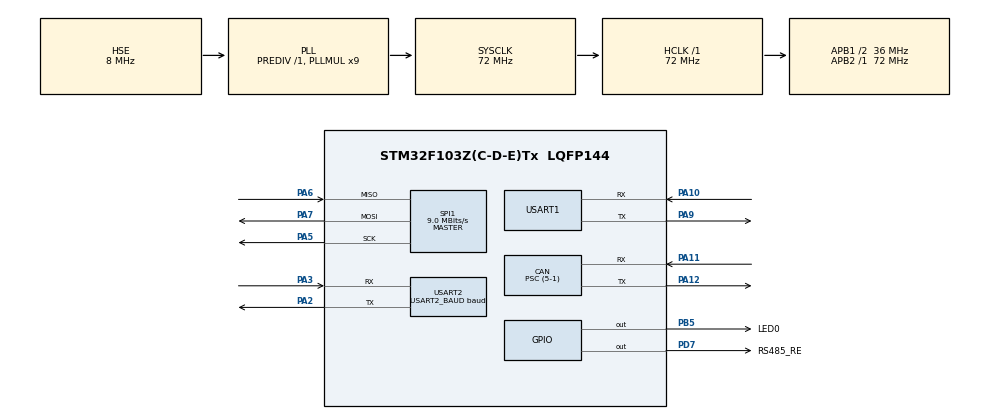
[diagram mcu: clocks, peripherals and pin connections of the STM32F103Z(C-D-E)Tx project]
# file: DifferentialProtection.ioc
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CAN.BS1=CAN_BS1_9TQ
CAN.BS2=CAN_BS2_8TQ
CAN.CalculateBaudRate=500000
CAN.CalculateTimeBit=1999.99
CAN.CalculateTimeQuantum=111.11111111111111
CAN.Mode=CAN_MODE_LOOPBACK
CAN.Prescaler=(5-1)
CAN.SJW=CAN_SJW_4TQ
Mcu.Family=STM32F1
Mcu.Name=STM32F103Z(C-D-E)Tx
Mcu.Package=LQFP144
Mcu.UserConstants=TIMER3_PSC,(72-1);TIMER3_PERIOD,10000;USART2_BAUD,115200
NVIC.CAN1_RX1_IRQn=true\:0\:0\:false\:false\:true\:true\:true
NVIC.PriorityGroup=NVIC_PRIORITYGROUP_2
NVIC.SPI1_IRQn=true\:0\:0\:false\:false\:true\:true\:true
NVIC.TIM3_IRQn=true\:0\:1\:false\:false\:true\:true\:true
NVIC.USART1_IRQn=true\:0\:0\:false\:false\:true\:true\:true
NVIC.USART2_IRQn=true\:0\:0\:false\:false\:true\:true\:true
OSC_IN.Mode=HSE-External-Oscillator
OSC_IN.Signal=RCC_OSC_IN
OSC_OUT.Mode=HSE-External-Oscillator
OSC_OUT.Signal=RCC_OSC_OUT
PA10.Mode=Asynchronous
PA10.Signal=USART1_RX
PA11.Mode=CAN_Activate
PA11.Signal=CAN_RX
PA12.Mode=CAN_Activate
PA12.Signal=CAN_TX
PA13.Mode=JTAG_5_pins
PA13.Signal=SYS_JTMS-SWDIO
PA14.Mode=JTAG_5_pins
PA14.Signal=SYS_JTCK-SWCLK
PA15.Mode=JTAG_5_pins
PA15.Signal=SYS_JTDI
PA2.Mode=Asynchronous
PA2.Signal=USART2_TX
PA3.Mode=Asynchronous
PA3.Signal=USART2_RX
PA5.Mode=Full_Duplex_Master
PA5.Signal=SPI1_SCK
PA6.Mode=Full_Duplex_Master
PA6.Signal=SPI1_MISO
PA7.Mode=Full_Duplex_Master
PA7.Signal=SPI1_MOSI
PA9.Mode=Asynchronous
PA9.Signal=USART1_TX
PB3.Mode=JTAG_5_pins
PB3.Signal=SYS_JTDO-TRACESWO
PB4.Mode=JTAG_5_pins
PB4.Signal=SYS_NJTRST
PB5.GPIO_Label=LED0
PB5.GPIO_PuPd=GPIO_PULLDOWN
PB5.PinState=GPIO_PIN_RESET
PB5.Signal=GPIO_Output
PC14-OSC32_IN.Mode=LSE-External-Oscillator
PC14-OSC32_IN.Signal=RCC_OSC32_IN
PC15-OSC32_OUT.Mode=LSE-External-Oscillator
PC15-OSC32_OUT.Signal=RCC_OSC32_OUT
PD7.GPIO_Label=RS485_RE
PD7.GPIO_Speed=GPIO_SPEED_FREQ_HIGH
PD7.PinState=GPIO_PIN_RESET
PD7.Signal=GPIO_Output
ProjectManager.HeapSize=0x200
ProjectManager.StackSize=0x400
ProjectManager.TargetToolchain=MDK-ARM V5.32
RCC.AHBFreq_Value=72000000
RCC.APB1CLKDivider=RCC_HCLK_DIV2
RCC.APB1Freq_Value=36000000
RCC.APB1TimFreq_Value=72000000
RCC.APB2Freq_Value=72000000
RCC.APB2TimFreq_Value=72000000
RCC.HCLKFreq_Value=72000000
RCC.PLLMUL=RCC_PLL_MUL9
RCC.PLLSourceVirtual=RCC_PLLSOURCE_HSE
RCC.SYSCLKFreq_VALUE=72000000
RCC.SYSCLKSource=RCC_SYSCLKSOURCE_PLLCLK
RCC.USBFreq_Value=72000000
SPI1.BaudRatePrescaler=SPI_BAUDRATEPRESCALER_8
SPI1.CalculateBaudRate=9.0 MBits/s
SPI1.Direction=SPI_DIRECTION_2LINES
SPI1.Mode=SPI_MODE_MASTER
SPI1.VirtualType=VM_MASTER
TIM3.AutoReloadPreload=TIM_AUTORELOAD_PRELOAD_ENABLE
TIM3.Period=TIMER3_PERIOD
TIM3.Prescaler=TIMER3_PSC
USART1.VirtualMode=VM_ASYNC
USART2.BaudRate=USART2_BAUD
USART2.VirtualMode=VM_ASYNC
VP_TIM3_VS_ClockSourceINT.Mode=Internal
board=custom

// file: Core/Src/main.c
/* USER CODE BEGIN Header */
/**
 ******************************************************************************
 * @file           : main.c
 * @brief          : Main program body
 ******************************************************************************
 * @attention
 *
 * <h2><center>&copy; Copyright (c) 2021 STMicroelectronics.
 * All rights reserved.</center></h2>
 *
 * This software component is licensed by ST under BSD 3-Clause license,
 * the "License"; You may not use this file except in compliance with the
 * License. You may obtain a copy of the License at:
 *                        opensource.org/licenses/BSD-3-Clause
 *
 ******************************************************************************
 */
/* USER CODE END Header */
#include "main.h"
#include "can.h"
#include "spi.h"
#include "tim.h"
#include "usart.h"
#include "gpio.h"

/* USER CODE BEGIN Includes */
#include "sys.h"
#include "modbus.h"
/* USER CODE END Includes */

void SystemClock_Config(void);

int main(void)
{

  /* MCU Configuration--------------------------------------------------------*/

  /* Reset of all peripherals, Initializes the Flash interface and the Systick. */
  HAL_Init();

  /* Configure the system clock */
  SystemClock_Config();

  /* Initialize all configured peripherals */
  MX_GPIO_Init();
  MX_CAN_Init();
  MX_SPI1_Init();
  MX_USART1_UART_Init();
  MX_USART2_UART_Init();
  MX_TIM3_Init();
  /* USER CODE BEGIN 2 */
  System_Init();
  /* USER CODE END 2 */

  /* Infinite loop */
  while (1)
  {

    /* USER CODE BEGIN 3 */
    if (ust.wait_task_main != NO_MSG)
    {
      Modbus_Main_Process();
    }
  }
  /* USER CODE END 3 */
}

void SystemClock_Config(void)
{
  RCC_OscInitTypeDef RCC_OscInitStruct = {0};
  RCC_ClkInitTypeDef RCC_ClkInitStruct = {0};

  /** Initializes the RCC Oscillators according to the specified parameters
  * in the RCC_OscInitTypeDef structure.
  */
  RCC_OscInitStruct.OscillatorType = RCC_OSCILLATORTYPE_HSE;
  RCC_OscInitStruct.HSEState = RCC_HSE_ON;
  RCC_OscInitStruct.HSEPredivValue = RCC_HSE_PREDIV_DIV1;
  RCC_OscInitStruct.HSIState = RCC_HSI_ON;
  RCC_OscInitStruct.PLL.PLLState = RCC_PLL_ON;
  RCC_OscInitStruct.PLL.PLLSource = RCC_PLLSOURCE_HSE;
  RCC_OscInitStruct.PLL.PLLMUL = RCC_PLL_MUL9;
  if (HAL_RCC_OscConfig(&RCC_OscInitStruct) != HAL_OK)
  {
    Error_Handler();
  }
  /** Initializes the CPU, AHB and APB buses clocks
  */
  RCC_ClkInitStruct.ClockType = RCC_CLOCKTYPE_HCLK|RCC_CLOCKTYPE_SYSCLK
                              |RCC_CLOCKTYPE_PCLK1|RCC_CLOCKTYPE_PCLK2;
  RCC_ClkInitStruct.SYSCLKSource = RCC_SYSCLKSOURCE_PLLCLK;
  RCC_ClkInitStruct.AHBCLKDivider = RCC_SYSCLK_DIV1;
  RCC_ClkInitStruct.APB1CLKDivider = RCC_HCLK_DIV2;
  RCC_ClkInitStruct.APB2CLKDivider = RCC_HCLK_DIV1;

  if (HAL_RCC_ClockConfig(&RCC_ClkInitStruct, FLASH_LATENCY_2) != HAL_OK)
  {
    Error_Handler();
  }
}

void Error_Handler(void)
{
  __disable_irq();
  while (1)
  {
  }
}

/************************ (C) COPYRIGHT STMicroelectronics *****END OF FILE****/
